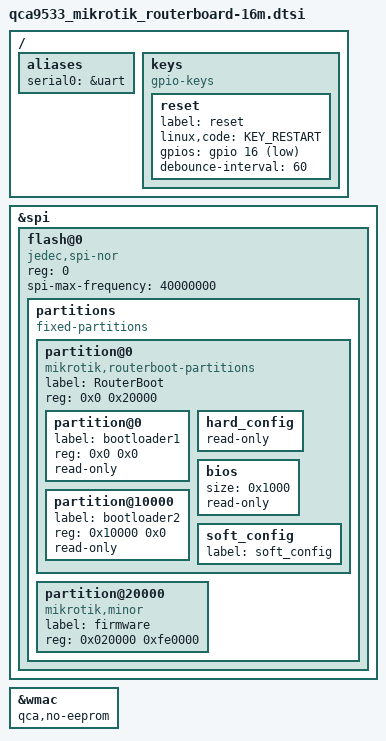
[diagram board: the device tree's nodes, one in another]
// SPDX-License-Identifier: GPL-2.0-or-later OR MIT

#include "qca953x.dtsi"

#include <dt-bindings/gpio/gpio.h>
#include <dt-bindings/input/input.h>

/ {
	aliases {
		serial0 = &uart;
	};

	keys {
		compatible = "gpio-keys";

		reset {
			label = "reset";
			linux,code = <KEY_RESTART>;
			gpios = <&gpio 16 GPIO_ACTIVE_LOW>;
			debounce-interval = <60>;
		};
	};
};

&spi {
	status = "okay";

	flash@0 {
		compatible = "jedec,spi-nor";
		reg = <0>;
		spi-max-frequency = <40000000>;

		partitions {
			compatible = "fixed-partitions";
			#address-cells = <1>;
			#size-cells = <1>;

			partition@0 {
				label = "RouterBoot";
				reg = <0x0 0x20000>;
				compatible = "mikrotik,routerboot-partitions";
				#address-cells = <1>;
				#size-cells = <1>;

				partition@0 {
					label = "bootloader1";
					reg = <0x0 0x0>;
					read-only;
				};

				hard_config: hard_config {
					read-only;
				};

				bios {
					size = <0x1000>;
					read-only;
				};

				partition@10000 {
					label = "bootloader2";
					reg = <0x10000 0x0>;
					read-only;
				};

				soft_config {
					label = "soft_config";
				};
			};

			partition@20000 {
				compatible = "mikrotik,minor";
				label = "firmware";
				reg = <0x020000 0xfe0000>;
			};
		};
	};
};

&wmac {
	status = "okay";

	qca,no-eeprom;
};
